VERSION ""

NS_ :

BS_:

BU_: ECU Display VCU SteeringWheel WirelessGateway DATA_COLLECTION_INTEGRAL VEHICLE_LOGGER PDM FanController BMS_Master

BO_ 1289 Debug9: 5 ECU
 SG_ LogicState_RR : 24|4@1+ (1,0) [0|15] "" Vector__XXX
 SG_ LogicState_RL : 28|4@1+ (1,0) [0|15] "" Vector__XXX
 SG_ LogicState_FR : 32|4@1+ (1,0) [0|15] "" Vector__XXX
 SG_ LogicState_FL : 36|4@1+ (1,0) [0|15] "" Vector__XXX
 SG_ FR_AMK_bEnable : 20|1@1+ (1,0) [0|1] "" Vector__XXX
 SG_ FL_AMK_bEnable : 21|1@1+ (1,0) [0|1] "" Vector__XXX
 SG_ RR_AMK_bEnable : 22|1@1+ (1,0) [0|1] "" Vector__XXX
 SG_ RL_AMK_bEnable : 23|1@1+ (1,0) [0|1] "" Vector__XXX
 SG_ FR_AMK_bQuitInverterOn : 16|1@1+ (1,0) [0|1] "" Vector__XXX
 SG_ FL_AMK_bQuitInverterOn : 17|1@1+ (1,0) [0|1] "" Vector__XXX
 SG_ RR_AMK_bQuitInverterOn : 18|1@1+ (1,0) [0|1] "" Vector__XXX
 SG_ RL_AMK_bQuitInverterOn : 19|1@1+ (1,0) [0|1] "" Vector__XXX
 SG_ FR_AMK_bQuitDcOn : 12|1@1+ (1,0) [0|1] "" Vector__XXX
 SG_ FL_AMK_bQuitDcOn : 13|1@1+ (1,0) [0|1] "" Vector__XXX
 SG_ RR_AMK_bQuitDcOn : 14|1@1+ (1,0) [0|1] "" Vector__XXX
 SG_ RL_AMK_bQuitDcOn : 15|1@1+ (1,0) [0|1] "" Vector__XXX
 SG_ FR_AMK_bSystemReady : 8|1@1+ (1,0) [0|1] "" Vector__XXX
 SG_ FL_AMK_bSystemReady : 9|1@1+ (1,0) [0|1] "" Vector__XXX
 SG_ RR_AMK_bSystemReady : 10|1@1+ (1,0) [0|1] "" Vector__XXX
 SG_ RL_AMK_bSystemReady : 11|1@1+ (1,0) [0|1] "" Vector__XXX
 SG_ FR_AMK_bError : 0|1@1+ (1,0) [0|1] "" Vector__XXX
 SG_ FL_AMK_bError : 1|1@1+ (1,0) [0|1] "" Vector__XXX
 SG_ RR_AMK_bError : 2|1@1+ (1,0) [0|1] "" Vector__XXX
 SG_ RL_AMK_bError : 3|1@1+ (1,0) [0|1] "" Vector__XXX
 SG_ ModeFlag : 4|4@1- (1,0) [-8|7] "" Vector__XXX

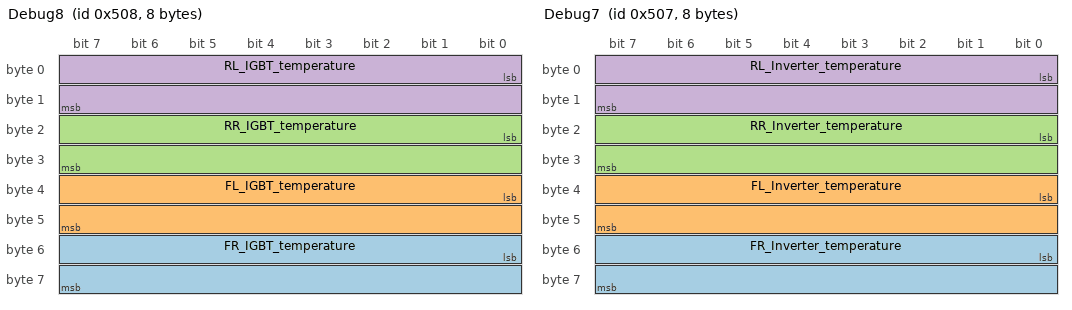
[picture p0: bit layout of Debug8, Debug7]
BO_ 1288 Debug8: 8 ECU
 SG_ FR_IGBT_temperature : 48|16@1- (0.1,0) [-3276.8|3276.7] "degC" Vector__XXX
 SG_ FL_IGBT_temperature : 32|16@1- (0.1,0) [-3276.8|3276.7] "degC" Vector__XXX
 SG_ RR_IGBT_temperature : 16|16@1- (0.1,0) [-3276.8|3276.7] "degC" Vector__XXX
 SG_ RL_IGBT_temperature : 0|16@1- (0.1,0) [-3276.8|3276.7] "degC" Vector__XXX

BO_ 1287 Debug7: 8 ECU
 SG_ FR_Inverter_temperature : 48|16@1- (0.1,0) [-3276.8|3276.7] "degC" Vector__XXX
 SG_ FL_Inverter_temperature : 32|16@1- (0.1,0) [-3276.8|3276.7] "degC" Vector__XXX
 SG_ RR_Inverter_temperature : 16|16@1- (0.1,0) [-3276.8|3276.7] "degC" Vector__XXX
 SG_ RL_Inverter_temperature : 0|16@1- (0.1,0) [-3276.8|3276.7] "degC" Vector__XXX

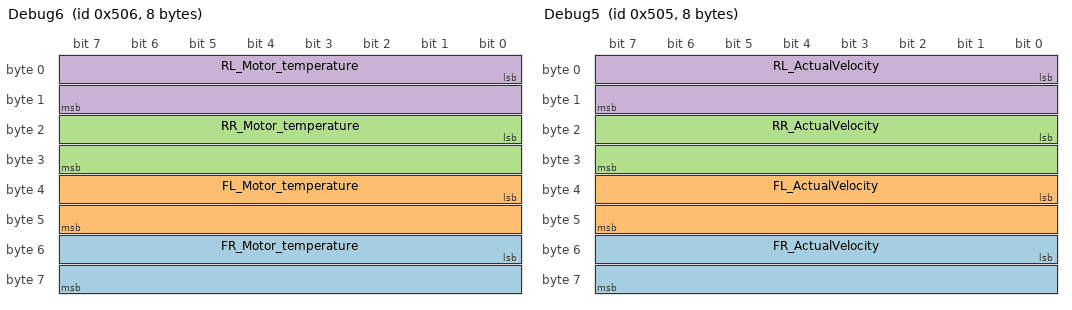
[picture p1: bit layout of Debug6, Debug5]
BO_ 1286 Debug6: 8 ECU
 SG_ FR_Motor_temperature : 48|16@1- (0.1,0) [-3276.8|3276.7] "degC" Vector__XXX
 SG_ FL_Motor_temperature : 32|16@1- (0.1,0) [-3276.8|3276.7] "degC" Vector__XXX
 SG_ RR_Motor_temperature : 16|16@1- (0.1,0) [-3276.8|3276.7] "degC" Vector__XXX
 SG_ RL_Motor_temperature : 0|16@1- (0.1,0) [-3276.8|3276.7] "degC" Vector__XXX

BO_ 1285 Debug5: 8 ECU
 SG_ FR_ActualVelocity : 48|16@1- (1,0) [-32768|32767] "" Vector__XXX
 SG_ FL_ActualVelocity : 32|16@1- (1,0) [-32768|32767] "" Vector__XXX
 SG_ RR_ActualVelocity : 16|16@1- (1,0) [-32768|32767] "" Vector__XXX
 SG_ RL_ActualVelocity : 0|16@1- (1,0) [-32768|32767] "" Vector__XXX

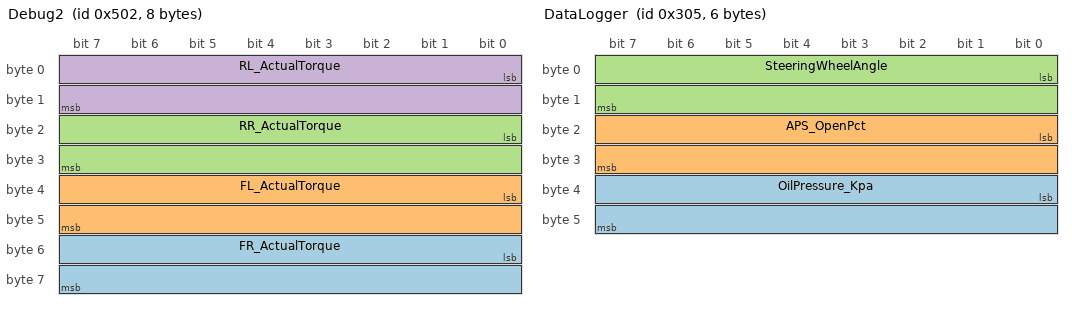
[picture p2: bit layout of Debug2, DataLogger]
BO_ 1282 Debug2: 8 ECU
 SG_ FR_ActualTorque : 48|16@1- (1,0) [-32768|32767] "0.1%Mn" Vector__XXX
 SG_ FL_ActualTorque : 32|16@1- (1,0) [-32768|32767] "0.1%Mn" Vector__XXX
 SG_ RR_ActualTorque : 16|16@1- (1,0) [-32768|32767] "0.1%Mn" Vector__XXX
 SG_ RL_ActualTorque : 0|16@1- (1,0) [-32768|32767] "0.1%Mn" Vector__XXX

BO_ 773 DataLogger: 6 ECU
 SG_ OilPressure_Kpa : 32|16@1+ (0.001,0) [0|65.535] "Kpa" Vector__XXX
 SG_ APS_OpenPct : 16|16@1+ (0.1,0) [0|6553.5] "%" Vector__XXX
 SG_ SteeringWheelAngle : 0|16@1- (0.1,0) [-3276.8|3276.7] "deg" Vector__XXX

BO_ 1284 Debug4: 8 ECU
 SG_ Diagnostic_number_4 : 32|32@1+ (1,0) [0|4294967295] "" Vector__XXX
 SG_ Diagnostic_number_3 : 0|32@1+ (1,0) [0|4294967295] "" Vector__XXX

BO_ 1283 Debug3: 8 ECU
 SG_ Diagnostic_number_2 : 32|32@1+ (1,0) [0|4294967295] "" Vector__XXX
 SG_ Diagnostic_number_1 : 0|32@1+ (1,0) [0|4294967295] "" Vector__XXX

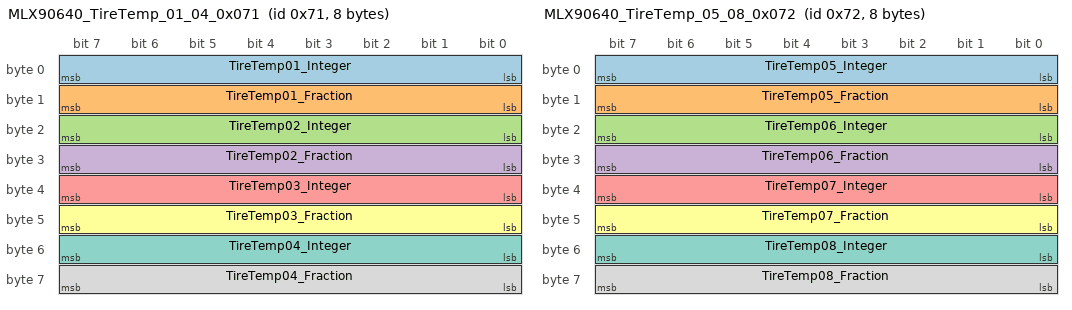
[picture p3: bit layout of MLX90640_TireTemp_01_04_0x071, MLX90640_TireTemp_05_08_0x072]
BO_ 113 MLX90640_TireTemp_01_04_0x071: 8 DATA_COLLECTION_INTEGRAL
 SG_ TireTemp01_Integer : 0|8@1+ (1,0) [0|255] "degC" Display,WirelessGateway,VEHICLE_LOGGER
 SG_ TireTemp01_Fraction : 8|8@1+ (0.01,0) [0|0.99] "degC" Display,WirelessGateway,VEHICLE_LOGGER
 SG_ TireTemp02_Integer : 16|8@1+ (1,0) [0|255] "degC" Display,WirelessGateway,VEHICLE_LOGGER
 SG_ TireTemp02_Fraction : 24|8@1+ (0.01,0) [0|0.99] "degC" Display,WirelessGateway,VEHICLE_LOGGER
 SG_ TireTemp03_Integer : 32|8@1+ (1,0) [0|255] "degC" Display,WirelessGateway,VEHICLE_LOGGER
 SG_ TireTemp03_Fraction : 40|8@1+ (0.01,0) [0|0.99] "degC" Display,WirelessGateway,VEHICLE_LOGGER
 SG_ TireTemp04_Integer : 48|8@1+ (1,0) [0|255] "degC" Display,WirelessGateway,VEHICLE_LOGGER
 SG_ TireTemp04_Fraction : 56|8@1+ (0.01,0) [0|0.99] "degC" Display,WirelessGateway,VEHICLE_LOGGER

BO_ 114 MLX90640_TireTemp_05_08_0x072: 8 DATA_COLLECTION_INTEGRAL
 SG_ TireTemp05_Integer : 0|8@1+ (1,0) [0|255] "degC" Display,WirelessGateway,VEHICLE_LOGGER
 SG_ TireTemp05_Fraction : 8|8@1+ (0.01,0) [0|0.99] "degC" Display,WirelessGateway,VEHICLE_LOGGER
 SG_ TireTemp06_Integer : 16|8@1+ (1,0) [0|255] "degC" Display,WirelessGateway,VEHICLE_LOGGER
 SG_ TireTemp06_Fraction : 24|8@1+ (0.01,0) [0|0.99] "degC" Display,WirelessGateway,VEHICLE_LOGGER
 SG_ TireTemp07_Integer : 32|8@1+ (1,0) [0|255] "degC" Display,WirelessGateway,VEHICLE_LOGGER
 SG_ TireTemp07_Fraction : 40|8@1+ (0.01,0) [0|0.99] "degC" Display,WirelessGateway,VEHICLE_LOGGER
 SG_ TireTemp08_Integer : 48|8@1+ (1,0) [0|255] "degC" Display,WirelessGateway,VEHICLE_LOGGER
 SG_ TireTemp08_Fraction : 56|8@1+ (0.01,0) [0|0.99] "degC" Display,WirelessGateway,VEHICLE_LOGGER

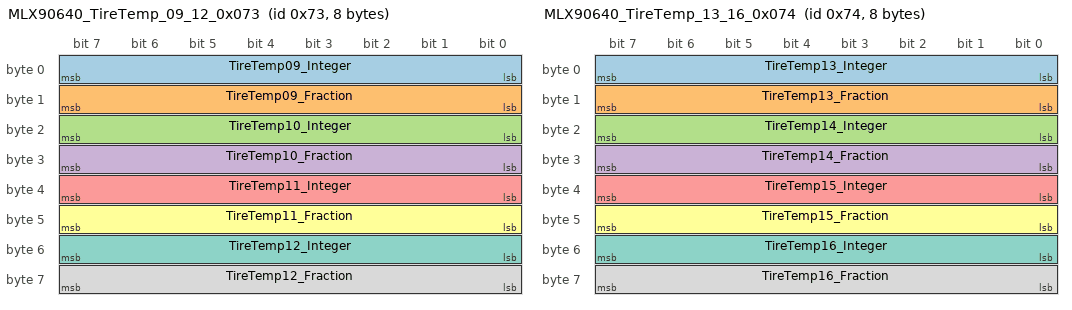
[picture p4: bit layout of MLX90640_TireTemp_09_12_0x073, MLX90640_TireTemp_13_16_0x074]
BO_ 115 MLX90640_TireTemp_09_12_0x073: 8 DATA_COLLECTION_INTEGRAL
 SG_ TireTemp09_Integer : 0|8@1+ (1,0) [0|255] "degC" Display,WirelessGateway,VEHICLE_LOGGER
 SG_ TireTemp09_Fraction : 8|8@1+ (0.01,0) [0|0.99] "degC" Display,WirelessGateway,VEHICLE_LOGGER
 SG_ TireTemp10_Integer : 16|8@1+ (1,0) [0|255] "degC" Display,WirelessGateway,VEHICLE_LOGGER
 SG_ TireTemp10_Fraction : 24|8@1+ (0.01,0) [0|0.99] "degC" Display,WirelessGateway,VEHICLE_LOGGER
 SG_ TireTemp11_Integer : 32|8@1+ (1,0) [0|255] "degC" Display,WirelessGateway,VEHICLE_LOGGER
 SG_ TireTemp11_Fraction : 40|8@1+ (0.01,0) [0|0.99] "degC" Display,WirelessGateway,VEHICLE_LOGGER
 SG_ TireTemp12_Integer : 48|8@1+ (1,0) [0|255] "degC" Display,WirelessGateway,VEHICLE_LOGGER
 SG_ TireTemp12_Fraction : 56|8@1+ (0.01,0) [0|0.99] "degC" Display,WirelessGateway,VEHICLE_LOGGER

BO_ 116 MLX90640_TireTemp_13_16_0x074: 8 DATA_COLLECTION_INTEGRAL
 SG_ TireTemp13_Integer : 0|8@1+ (1,0) [0|255] "degC" Display,WirelessGateway,VEHICLE_LOGGER
 SG_ TireTemp13_Fraction : 8|8@1+ (0.01,0) [0|0.99] "degC" Display,WirelessGateway,VEHICLE_LOGGER
 SG_ TireTemp14_Integer : 16|8@1+ (1,0) [0|255] "degC" Display,WirelessGateway,VEHICLE_LOGGER
 SG_ TireTemp14_Fraction : 24|8@1+ (0.01,0) [0|0.99] "degC" Display,WirelessGateway,VEHICLE_LOGGER
 SG_ TireTemp15_Integer : 32|8@1+ (1,0) [0|255] "degC" Display,WirelessGateway,VEHICLE_LOGGER
 SG_ TireTemp15_Fraction : 40|8@1+ (0.01,0) [0|0.99] "degC" Display,WirelessGateway,VEHICLE_LOGGER
 SG_ TireTemp16_Integer : 48|8@1+ (1,0) [0|255] "degC" Display,WirelessGateway,VEHICLE_LOGGER
 SG_ TireTemp16_Fraction : 56|8@1+ (0.01,0) [0|0.99] "degC" Display,WirelessGateway,VEHICLE_LOGGER

BO_ 769 GPS_Speed: 2 Display
 SG_ GroundSpeed : 0|16@1+ (0.1,0) [0|300] "km/h" ECU,WirelessGateway

BO_ 103 GPS_Position_0x067: 8 Display
 SG_ GPS_Latitude : 0|32@1- (0.0000001,0) [-90|90] "deg" WirelessGateway
 SG_ GPS_Longitude : 32|32@1- (0.0000001,0) [-180|180] "deg" WirelessGateway

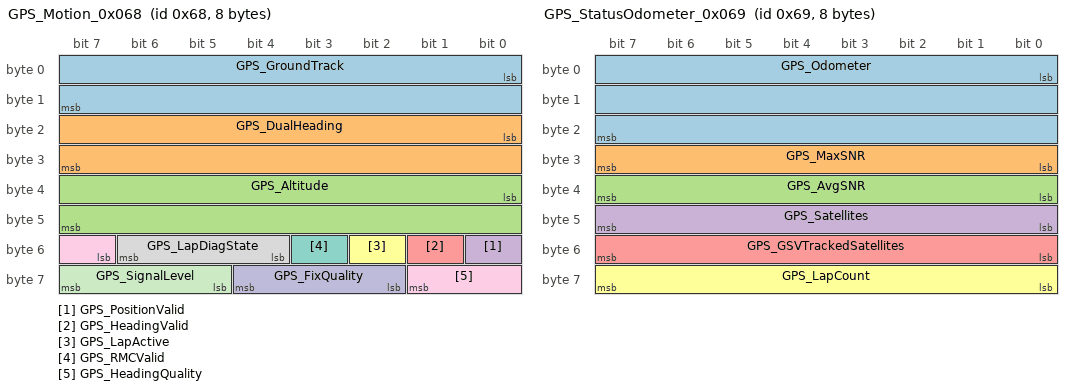
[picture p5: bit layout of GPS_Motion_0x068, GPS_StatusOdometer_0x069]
BO_ 104 GPS_Motion_0x068: 8 Display
 SG_ GPS_GroundTrack : 0|16@1+ (0.01,0) [0|359.99] "deg" WirelessGateway
 SG_ GPS_DualHeading : 16|16@1+ (0.01,0) [0|359.99] "deg" WirelessGateway
 SG_ GPS_Altitude : 32|16@1- (0.1,0) [-3276.8|3276.7] "m" WirelessGateway
 SG_ GPS_PositionValid : 48|1@1+ (1,0) [0|1] "" WirelessGateway
 SG_ GPS_HeadingValid : 49|1@1+ (1,0) [0|1] "" WirelessGateway
 SG_ GPS_LapActive : 50|1@1+ (1,0) [0|1] "" WirelessGateway
 SG_ GPS_RMCValid : 51|1@1+ (1,0) [0|1] "" WirelessGateway
 SG_ GPS_LapDiagState : 52|3@1+ (1,0) [0|6] "" WirelessGateway
 SG_ GPS_HeadingQuality : 55|3@1+ (1,0) [0|7] "" WirelessGateway
 SG_ GPS_FixQuality : 58|3@1+ (1,0) [0|7] "" WirelessGateway
 SG_ GPS_SignalLevel : 61|3@1+ (1,0) [0|4] "" WirelessGateway

BO_ 105 GPS_StatusOdometer_0x069: 8 Display
 SG_ GPS_Odometer : 0|24@1+ (0.1,0) [0|1677721.5] "km" WirelessGateway
 SG_ GPS_MaxSNR : 24|8@1- (1,0) [-128|127] "dB-Hz" WirelessGateway
 SG_ GPS_AvgSNR : 32|8@1- (1,0) [-128|127] "dB-Hz" WirelessGateway
 SG_ GPS_Satellites : 40|8@1+ (1,0) [0|255] "" WirelessGateway
 SG_ GPS_GSVTrackedSatellites : 48|8@1+ (1,0) [0|255] "" WirelessGateway
 SG_ GPS_LapCount : 56|8@1+ (1,0) [0|255] "lap" WirelessGateway

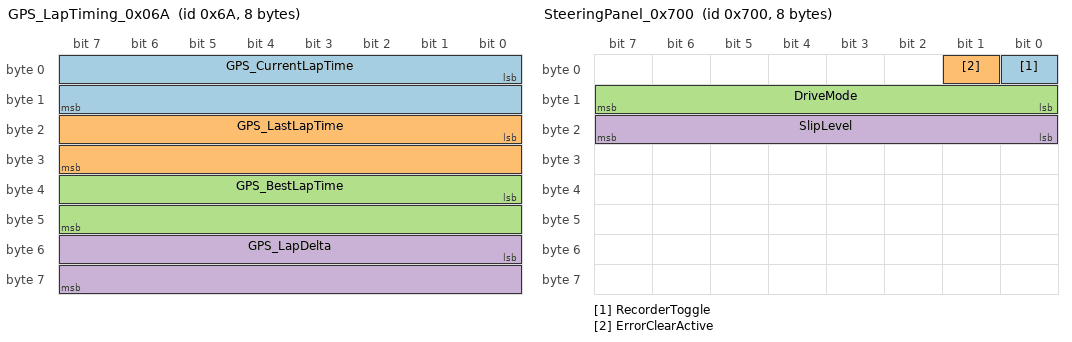
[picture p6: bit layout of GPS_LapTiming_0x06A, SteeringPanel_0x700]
BO_ 106 GPS_LapTiming_0x06A: 8 Display
 SG_ GPS_CurrentLapTime : 0|16@1+ (0.01,0) [0|655.35] "s" WirelessGateway
 SG_ GPS_LastLapTime : 16|16@1+ (0.01,0) [0|655.35] "s" WirelessGateway
 SG_ GPS_BestLapTime : 32|16@1+ (0.01,0) [0|655.35] "s" WirelessGateway
 SG_ GPS_LapDelta : 48|16@1- (0.01,0) [-327.68|327.67] "s" WirelessGateway

BO_ 1792 SteeringPanel_0x700: 8 SteeringWheel
 SG_ RecorderToggle : 0|1@1+ (1,0) [0|1] "" VCU,Display
 SG_ ErrorClearActive : 1|1@1+ (1,0) [0|1] "" VCU,Display
 SG_ DriveMode : 8|8@1+ (1,0) [0|3] "" VCU,Display
 SG_ SlipLevel : 16|8@1+ (1,0) [0|7] "" VCU,Display

BO_ 1924 DriveMode_0x784: 8 SteeringWheel
 SG_ DriveMode : 0|8@1+ (1,0) [0|3] "" VCU,Display

BO_ 784 DriveMode_Request: 8 Display
 SG_ DriveModeCode : 0|8@1+ (1,0) [48|51] "" ECU

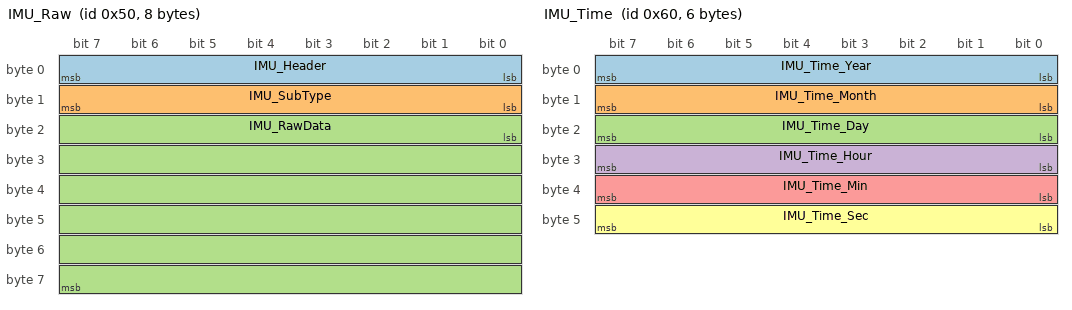
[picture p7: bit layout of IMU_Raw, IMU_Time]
BO_ 80 IMU_Raw: 8 Display
 SG_ IMU_Header : 0|8@1+ (1,0) [85|85] "" Vector__XXX
 SG_ IMU_SubType : 8|8@1+ (1,0) [80|84] "" Vector__XXX
 SG_ IMU_RawData : 16|48@1+ (1,0) [0|281474976710655] "" Vector__XXX

BO_ 96 IMU_Time: 6 Display
 SG_ IMU_Time_Year : 0|8@1+ (1,2000) [0|99] "" Vector__XXX
 SG_ IMU_Time_Month : 8|8@1+ (1,0) [1|12] "" Vector__XXX
 SG_ IMU_Time_Day : 16|8@1+ (1,0) [1|31] "" Vector__XXX
 SG_ IMU_Time_Hour : 24|8@1+ (1,0) [0|23] "" Vector__XXX
 SG_ IMU_Time_Min : 32|8@1+ (1,0) [0|59] "" Vector__XXX
 SG_ IMU_Time_Sec : 40|8@1+ (1,0) [0|59] "" Vector__XXX

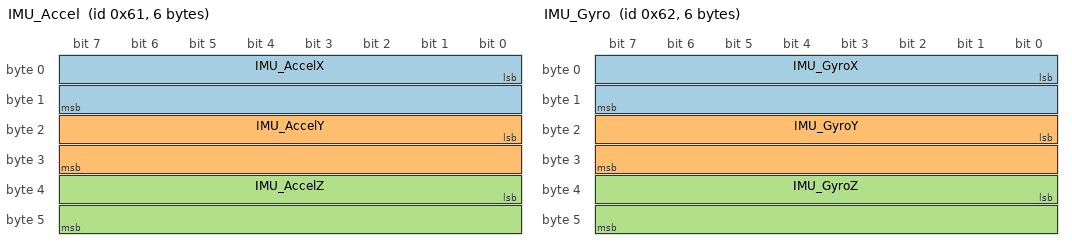
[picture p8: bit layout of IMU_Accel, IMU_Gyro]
BO_ 97 IMU_Accel: 6 Display
 SG_ IMU_AccelX : 0|16@1- (0.00048828125,0) [-16|16] "g" Vector__XXX
 SG_ IMU_AccelY : 16|16@1- (0.00048828125,0) [-16|16] "g" Vector__XXX
 SG_ IMU_AccelZ : 32|16@1- (0.00048828125,0) [-16|16] "g" Vector__XXX

BO_ 98 IMU_Gyro: 6 Display
 SG_ IMU_GyroX : 0|16@1- (0.0610352,0) [-2000|2000] "deg/s" Vector__XXX
 SG_ IMU_GyroY : 16|16@1- (0.0610352,0) [-2000|2000] "deg/s" Vector__XXX
 SG_ IMU_GyroZ : 32|16@1- (0.0610352,0) [-2000|2000] "deg/s" Vector__XXX

BO_ 99 IMU_Roll: 2 Display
 SG_ IMU_Angle_Roll : 0|16@1- (0.005493,0) [-180|180] "deg" Vector__XXX

BO_ 100 IMU_Pitch: 2 Display
 SG_ IMU_Angle_Pitch : 0|16@1- (0.005493,0) [-90|90] "deg" Vector__XXX

BO_ 101 IMU_Yaw: 2 Display
 SG_ IMU_Angle_Yaw : 0|16@1- (0.005493,0) [-180|180] "deg" Vector__XXX

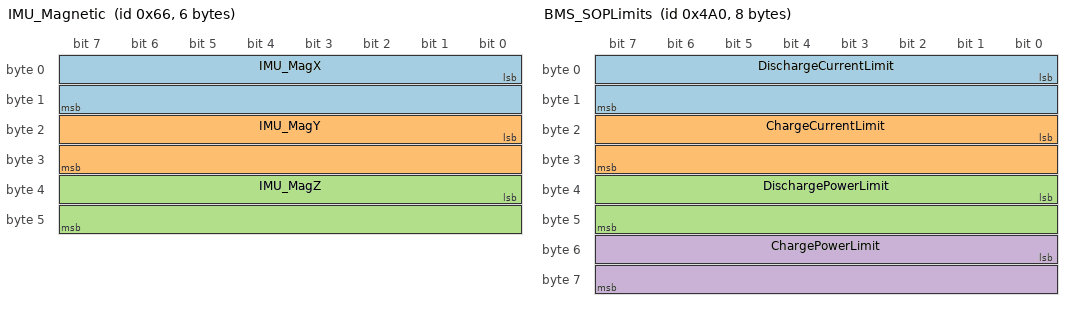
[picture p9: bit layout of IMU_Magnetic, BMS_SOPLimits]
BO_ 102 IMU_Magnetic: 6 Display
 SG_ IMU_MagX : 0|16@1- (1,0) [-32768|32767] "" Vector__XXX
 SG_ IMU_MagY : 16|16@1- (1,0) [-32768|32767] "" Vector__XXX
 SG_ IMU_MagZ : 32|16@1- (1,0) [-32768|32767] "" Vector__XXX

BO_ 1184 BMS_SOPLimits: 8 BMS_Master
 SG_ DischargeCurrentLimit : 0|16@1+ (0.1,0) [0|6553.5] "A" ECU
 SG_ ChargeCurrentLimit : 16|16@1+ (0.1,0) [0|6553.5] "A" ECU
 SG_ DischargePowerLimit : 32|16@1+ (0.1,0) [0|6553.5] "kW" ECU
 SG_ ChargePowerLimit : 48|16@1+ (0.1,0) [0|6553.5] "kW" ECU

BO_ 1187 BMS_SOPStatus: 8 BMS_Master
 SG_ SOPSequence : 0|4@1+ (1,0) [0|15] "" ECU
 SG_ SOPProtocolVersion : 4|4@1+ (1,0) [0|15] "" ECU
 SG_ LimitsValid : 8|1@1+ (1,0) [0|1] "" ECU
 SG_ DriveAllowed : 9|1@1+ (1,0) [0|1] "" ECU
 SG_ RegenAllowed : 10|1@1+ (1,0) [0|1] "" ECU
 SG_ OvercurrentLimitZero : 11|1@1+ (1,0) [0|1] "" ECU
 SG_ BMSFaultHold : 12|1@1+ (1,0) [0|1] "" ECU
 SG_ SOPAckRequired : 13|1@1+ (1,0) [0|1] "" ECU
 SG_ LimitsReduced : 14|1@1+ (1,0) [0|1] "" ECU
 SG_ BatteryState : 16|8@1+ (1,0) [0|255] "" ECU
 SG_ LimitReason : 24|16@1+ (1,0) [0|65535] "" ECU
 SG_ InputHealth : 40|8@1+ (1,0) [0|255] "" ECU
 SG_ InterventionLevel : 48|2@1+ (1,0) [0|3] "" ECU
 SG_ DischargeOvercurrentZero : 50|1@1+ (1,0) [0|1] "" ECU
 SG_ ChargeOvercurrentZero : 51|1@1+ (1,0) [0|1] "" ECU
 SG_ AckMissing : 52|1@1+ (1,0) [0|1] "" ECU
 SG_ AckFresh : 53|1@1+ (1,0) [0|1] "" ECU
 SG_ CurrentBelowClearThreshold : 54|1@1+ (1,0) [0|1] "" ECU
 SG_ SOPCRC8 : 56|8@1+ (1,0) [0|255] "" ECU

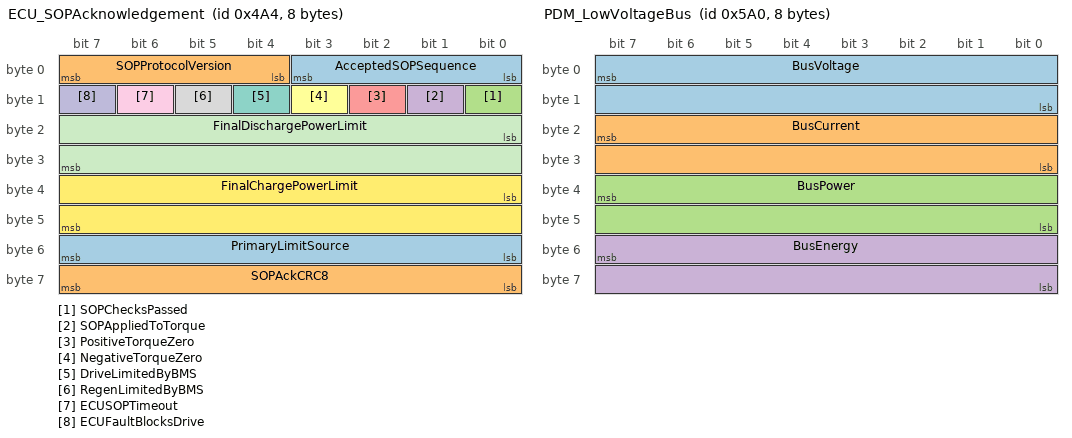
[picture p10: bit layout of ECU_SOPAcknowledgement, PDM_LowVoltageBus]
BO_ 1188 ECU_SOPAcknowledgement: 8 ECU
 SG_ AcceptedSOPSequence : 0|4@1+ (1,0) [0|15] "" BMS_Master
 SG_ SOPProtocolVersion : 4|4@1+ (1,0) [0|15] "" BMS_Master
 SG_ SOPChecksPassed : 8|1@1+ (1,0) [0|1] "" BMS_Master
 SG_ SOPAppliedToTorque : 9|1@1+ (1,0) [0|1] "" BMS_Master
 SG_ PositiveTorqueZero : 10|1@1+ (1,0) [0|1] "" BMS_Master
 SG_ NegativeTorqueZero : 11|1@1+ (1,0) [0|1] "" BMS_Master
 SG_ DriveLimitedByBMS : 12|1@1+ (1,0) [0|1] "" BMS_Master
 SG_ RegenLimitedByBMS : 13|1@1+ (1,0) [0|1] "" BMS_Master
 SG_ ECUSOPTimeout : 14|1@1+ (1,0) [0|1] "" BMS_Master
 SG_ ECUFaultBlocksDrive : 15|1@1+ (1,0) [0|1] "" BMS_Master
 SG_ FinalDischargePowerLimit : 16|16@1+ (0.1,0) [0|6553.5] "kW" BMS_Master
 SG_ FinalChargePowerLimit : 32|16@1+ (0.1,0) [0|6553.5] "kW" BMS_Master
 SG_ PrimaryLimitSource : 48|8@1+ (1,0) [0|255] "" BMS_Master
 SG_ SOPAckCRC8 : 56|8@1+ (1,0) [0|255] "" BMS_Master

BO_ 1440 PDM_LowVoltageBus: 8 PDM
 SG_ BusVoltage : 7|16@0- (0.001,0) [-32.768|32.767] "V" ECU
 SG_ BusCurrent : 23|16@0- (0.01,0) [-327.68|327.67] "A" ECU
 SG_ BusPower : 39|16@0+ (0.1,0) [0|6553.5] "W" ECU
 SG_ BusEnergy : 55|16@0+ (0.01,0) [0|655.35] "Wh" ECU

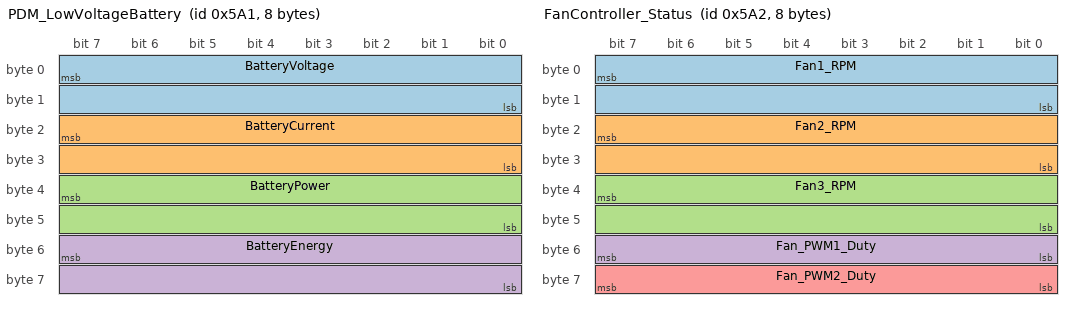
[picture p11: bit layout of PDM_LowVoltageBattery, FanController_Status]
BO_ 1441 PDM_LowVoltageBattery: 8 PDM
 SG_ BatteryVoltage : 7|16@0- (0.001,0) [-32.768|32.767] "V" ECU
 SG_ BatteryCurrent : 23|16@0- (0.01,0) [-327.68|327.67] "A" ECU
 SG_ BatteryPower : 39|16@0+ (0.1,0) [0|6553.5] "W" ECU
 SG_ BatteryEnergy : 55|16@0+ (0.01,0) [0|655.35] "Wh" ECU

BO_ 1442 FanController_Status: 8 FanController
 SG_ Fan1_RPM : 7|16@0+ (1,0) [0|65535] "rpm" ECU
 SG_ Fan2_RPM : 23|16@0+ (1,0) [0|65535] "rpm" ECU
 SG_ Fan3_RPM : 39|16@0+ (1,0) [0|65535] "rpm" ECU
 SG_ Fan_PWM1_Duty : 55|8@0+ (1,0) [0|100] "%" ECU
 SG_ Fan_PWM2_Duty : 63|8@0+ (1,0) [0|100] "%" ECU

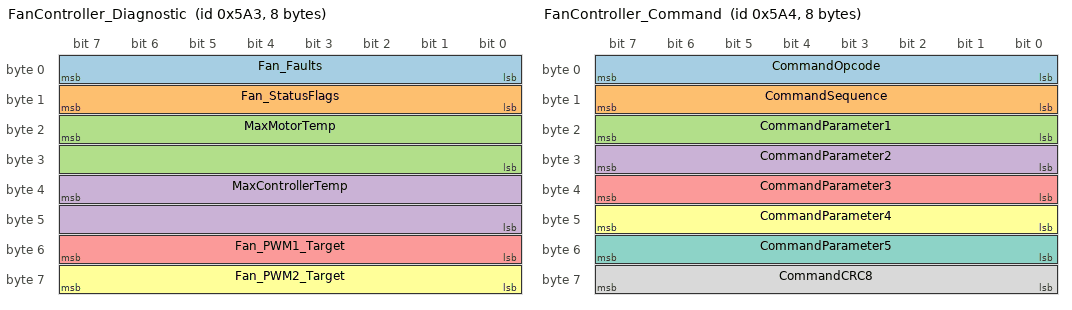
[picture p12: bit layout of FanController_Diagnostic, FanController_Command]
BO_ 1443 FanController_Diagnostic: 8 FanController
 SG_ Fan_Faults : 7|8@0+ (1,0) [0|255] "" ECU
 SG_ Fan_StatusFlags : 15|8@0+ (1,0) [0|255] "" ECU
 SG_ MaxMotorTemp : 23|16@0- (0.1,0) [-3276.8|3276.7] "degC" ECU
 SG_ MaxControllerTemp : 39|16@0- (0.1,0) [-3276.8|3276.7] "degC" ECU
 SG_ Fan_PWM1_Target : 55|8@0+ (1,0) [0|100] "%" ECU
 SG_ Fan_PWM2_Target : 63|8@0+ (1,0) [0|100] "%" ECU

BO_ 1444 FanController_Command: 8 ECU
 SG_ CommandOpcode : 0|8@1+ (1,0) [0|255] "" FanController
 SG_ CommandSequence : 8|8@1+ (1,0) [0|255] "" FanController
 SG_ CommandParameter1 : 16|8@1+ (1,0) [0|255] "" FanController
 SG_ CommandParameter2 : 24|8@1+ (1,0) [0|255] "" FanController
 SG_ CommandParameter3 : 32|8@1+ (1,0) [0|255] "" FanController
 SG_ CommandParameter4 : 40|8@1+ (1,0) [0|255] "" FanController
 SG_ CommandParameter5 : 48|8@1+ (1,0) [0|255] "" FanController
 SG_ CommandCRC8 : 56|8@1+ (1,0) [0|255] "" FanController

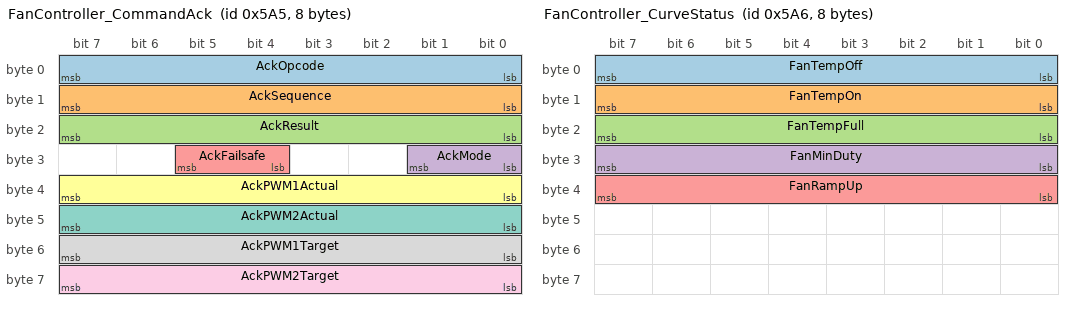
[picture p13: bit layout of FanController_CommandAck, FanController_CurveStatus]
BO_ 1445 FanController_CommandAck: 8 FanController
 SG_ AckOpcode : 0|8@1+ (1,0) [0|255] "" ECU
 SG_ AckSequence : 8|8@1+ (1,0) [0|255] "" ECU
 SG_ AckResult : 16|8@1+ (1,0) [0|255] "" ECU
 SG_ AckMode : 24|2@1+ (1,0) [0|3] "" ECU
 SG_ AckFailsafe : 28|2@1+ (1,0) [0|3] "" ECU
 SG_ AckPWM1Actual : 32|8@1+ (1,0) [0|100] "%" ECU
 SG_ AckPWM2Actual : 40|8@1+ (1,0) [0|100] "%" ECU
 SG_ AckPWM1Target : 48|8@1+ (1,0) [0|100] "%" ECU
 SG_ AckPWM2Target : 56|8@1+ (1,0) [0|100] "%" ECU

BO_ 1446 FanController_CurveStatus: 8 FanController
 SG_ FanTempOff : 0|8@1+ (1,0) [0|150] "degC" ECU
 SG_ FanTempOn : 8|8@1+ (1,0) [0|150] "degC" ECU
 SG_ FanTempFull : 16|8@1+ (1,0) [0|150] "degC" ECU
 SG_ FanMinDuty : 24|8@1+ (1,0) [0|100] "%" ECU
 SG_ FanRampUp : 32|8@1+ (1,0) [0|100] "%/s" ECU

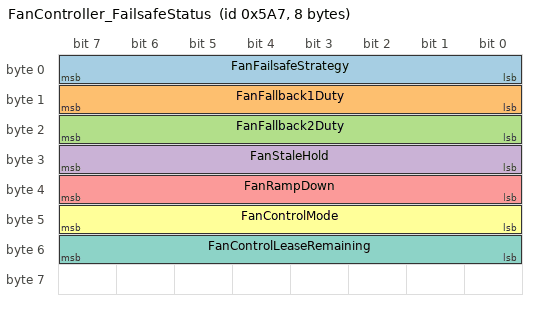
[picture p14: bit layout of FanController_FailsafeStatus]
BO_ 1447 FanController_FailsafeStatus: 8 FanController
 SG_ FanFailsafeStrategy : 0|8@1+ (1,0) [0|2] "" ECU
 SG_ FanFallback1Duty : 8|8@1+ (1,0) [0|100] "%" ECU
 SG_ FanFallback2Duty : 16|8@1+ (1,0) [0|100] "%" ECU
 SG_ FanStaleHold : 24|8@1+ (1,0) [0|30] "s" ECU
 SG_ FanRampDown : 32|8@1+ (1,0) [0|100] "%/s" ECU
 SG_ FanControlMode : 40|8@1+ (1,0) [0|2] "" ECU
 SG_ FanControlLeaseRemaining : 48|8@1+ (1,0) [0|60] "s" ECU

CM_ SG_ 1289 FR_AMK_bEnable "Front-right motor enable flag.";
CM_ SG_ 1288 FR_IGBT_temperature "Front-right IGBT temperature in degrees Celsius.";
CM_ SG_ 1287 FR_Inverter_temperature "Front-right inverter temperature in degrees Celsius.";
CM_ SG_ 1286 FR_Motor_temperature "Front-right motor temperature in degrees Celsius.";
CM_ SG_ 1282 FR_ActualTorque "Front-right actual motor torque.";
CM_ SG_ 773 OilPressure_Kpa "Oil pressure signal in kPa.";
CM_ SG_ 773 APS_OpenPct "Accelerator pedal opening percentage.";
CM_ SG_ 773 SteeringWheelAngle "Steering-wheel angle in degrees.";
CM_ BO_ 113 "MLX90640 right-front tire-temperature cells 1..4, standard CAN ID 0x071, DLC=8. R0..R3 map directly to cells 1..4 in payload order, from RF rightmost/outside to RF leftmost/inside. Bytes 0/2/4/6 are unsigned integer degC; bytes 1/3/5/7 are unsigned hundredths 0..99. Full temperature = Integer + Fraction.";
CM_ BO_ 114 "MLX90640 left-front tire-temperature cells 5..8, standard CAN ID 0x072, DLC=8. R0..R3 map directly to cells 5..8 in payload order, from LF rightmost/inside to LF leftmost/outside. Bytes 0/2/4/6 are unsigned integer degC; bytes 1/3/5/7 are unsigned hundredths 0..99. Full temperature = Integer + Fraction.";
CM_ BO_ 115 "MLX90640 left-rear tire-temperature cells 9..12, standard CAN ID 0x073, DLC=8. R0..R3 map directly to cells 9..12 in payload order, from LR leftmost/outside to LR rightmost/inside. Bytes 0/2/4/6 are unsigned integer degC; bytes 1/3/5/7 are unsigned hundredths 0..99. Full temperature = Integer + Fraction.";
CM_ BO_ 116 "MLX90640 right-rear tire-temperature cells 13..16, standard CAN ID 0x074, DLC=8. R0..R3 map directly to cells 13..16 in payload order, from RR leftmost/inside to RR rightmost/outside. Bytes 0/2/4/6 are unsigned integer degC; bytes 1/3/5/7 are unsigned hundredths 0..99. Full temperature = Integer + Fraction.";
CM_ BO_ 769 "Legacy-compatible GPS ground speed, standard CAN ID 0x301, DLC=2, Display->ECU/WirelessGateway, periodic 50 ms. Source is the latest NMEA RMC speed configured at 20 Hz; invalid RMC status or no RMC update for more than 500 ms transmits zero. The DLC remains 2 to avoid breaking the existing ECU receiver; additional GPS data use IDs 0x067 through 0x06A.";
CM_ SG_ 769 GroundSpeed "Bits 0..15, Intel little-endian, unsigned. RMC speed is parsed in knots, converted to 0.01 km/h internally, rounded to 0.1 km/h for CAN, then clamped to 0..300 km/h. Raw value = physical km/h / 0.1.";
CM_ BO_ 103 "GPS position snapshot, standard CAN ID 0x067, DLC=8, Display->WirelessGateway, periodic 50 ms. Latitude and longitude come from the latest valid 20 Hz RMC sentence and are encoded as signed 1e-7 degree integers.";
CM_ BO_ 104 "GPS motion, validity and compact quality snapshot, standard CAN ID 0x068, DLC=8, Display->WirelessGateway, periodic 50 ms. Ground track comes from RMC; dual-antenna heading is the most recent HPR value and its validity bit expires after 1.5 s. HPR is currently configured at 5 Hz. Signal level is the same 0..4 value used by the display bars.";
CM_ BO_ 105 "GPS reception status and persistent odometer snapshot, standard CAN ID 0x069, DLC=8, Display->WirelessGateway, periodic 50 ms. Odometer resolution is 0.1 km. Max/average SNR and tracked-satellite count come from the latest completed GSV window.";
CM_ BO_ 106 "GPS-derived lap timing snapshot, standard CAN ID 0x06A, DLC=8, Display->WirelessGateway, periodic 50 ms. Times use centiseconds. Unsigned lap times saturate at 655.35 s and signed delta saturates at -327.68..327.67 s.";
CM_ SG_ 104 GPS_RMCValid "1 means a valid-status RMC sentence has been received within the 500 ms freshness window; when 0, position/track fields may contain the last received values and GroundSpeed is transmitted as zero.";
CM_ SG_ 104 GPS_HeadingValid "1 means the dual-antenna HPR quality is accepted and the most recent HPR sentence is not older than 1.5 s.";
CM_ SG_ 104 GPS_LapDiagState "The same diagnostic state that drives the display lap indicator: 0=Inactive, 1=WaitArm, 2=Armed, 3=Approaching, 4=GateMiss, 5=ReversePass, 6=Crossed.";
CM_ BO_ 1792 "Steering wheel unified panel packet, standard CAN ID 0x700, DLC=8. Event-driven and sent only when panel data changes.";
CM_ SG_ 1792 RecorderToggle "PB12: 0=Idle, 1=ToggleRecorderCmd. A 250 ms one-shot pulse; Display acts only on the rising edge.";
CM_ SG_ 1792 ErrorClearActive "PB13: 0=Idle, 1=ErrorClear. A 250 ms one-shot pulse; Display acts only on the rising edge.";
CM_ SG_ 1792 DriveMode "Rotary switch S1-S4: 0=S1/S, 1=S2/Q, 2=S3/C, 3=S4/E, 255=Invalid.";
CM_ SG_ 1792 SlipLevel "PA1 ADC potentiometer quantized to eight levels: 0..7.";
CM_ BO_ 1924 "Steering wheel redundant drive-mode packet, standard CAN ID 0x784, DLC=8. Sent together with 0x700 when drive mode changes.";
CM_ SG_ 1924 DriveMode "Rotary switch S1-S4: 0=S1/S, 1=S2/Q, 2=S3/C, 3=S4/E, 255=Invalid.";
CM_ SG_ 784 DriveModeCode "Drive mode request: 48=S, 49=Q, 50=C, 51=E, Display->ECU";
CM_ SG_ 80 IMU_Header "Fixed frame header 0x55.";
CM_ SG_ 80 IMU_SubType "Packet type: 0x50=time, 0x51=acceleration, 0x52=angular velocity, 0x53=angle, 0x54=magnetic field.";
CM_ SG_ 80 IMU_RawData "Payload selected by IMU_SubType; see decoded packets 0x060 through 0x066.";
CM_ SG_ 96 IMU_Time_Year "Year offset from 2000, decoded from packet 0x050 with SubType 0x50.";
CM_ SG_ 97 IMU_AccelX "X-axis acceleration in g, decoded from packet 0x050 with SubType 0x51.";
CM_ SG_ 98 IMU_GyroX "X-axis angular velocity in deg/s, decoded from packet 0x050 with SubType 0x52.";
CM_ SG_ 99 IMU_Angle_Roll "Roll angle in degrees, decoded from packet 0x050 with SubType 0x53 and SubCmd 1.";
CM_ SG_ 100 IMU_Angle_Pitch "Pitch angle in degrees, decoded from packet 0x050 with SubType 0x53 and SubCmd 2.";
CM_ SG_ 101 IMU_Angle_Yaw "Yaw angle in degrees, decoded from packet 0x050 with SubType 0x53 and SubCmd 3.";
CM_ SG_ 102 IMU_MagX "Raw X-axis magnetic-field value, decoded from packet 0x050 with SubType 0x54.";

CM_ BO_ 1440 "Low-voltage bus status. All four fields at their invalid raw values mean the INA226 is offline or a read failed.";
CM_ BO_ 1441 "Low-voltage battery branch status. Energy is accumulated since MCU boot and is not battery state of charge.";
CM_ BO_ 1442 "Three fan speeds and two measured fan-side PWM duty cycles.";
CM_ BO_ 1443 "Fan faults, input validity, control mode, maximum temperatures and target duty cycles.";
CM_ BO_ 1444 "Fan control command. Byte 7 is CRC-8/SAE-J1850 over bytes 0 through 6.";
CM_ BO_ 1445 "Fan command acknowledgement and current control state.";
VAL_ 1444 CommandOpcode 1 "SetControl" 2 "SetCurve" 3 "SetFailsafe" 4 "RestoreDefaults" 5 "Query";
VAL_ 1445 AckResult 0 "OK" 1 "BadCRC" 2 "BadLength" 3 "BadValue" 4 "Unsupported" 5 "LeaseExpired";
VAL_ 1445 AckMode 0 "Auto" 1 "Manual" 2 "Off";
VAL_ 1445 AckFailsafe 0 "HoldLast" 1 "Fallback" 2 "Full";
VAL_ 1447 FanFailsafeStrategy 0 "HoldLast" 1 "Fallback" 2 "Full";
VAL_ 1447 FanControlMode 0 "Auto" 1 "Manual" 2 "Off";
VAL_ 1187 BatteryState 2 "SelfTest" 3 "Standby" 4 "Precharge" 5 "HighVoltageOn" 7 "FaultHold";
VAL_ 1187 InterventionLevel 0 "Normal" 1 "Derating" 2 "OvercurrentZero" 3 "FaultOrShutdown";
